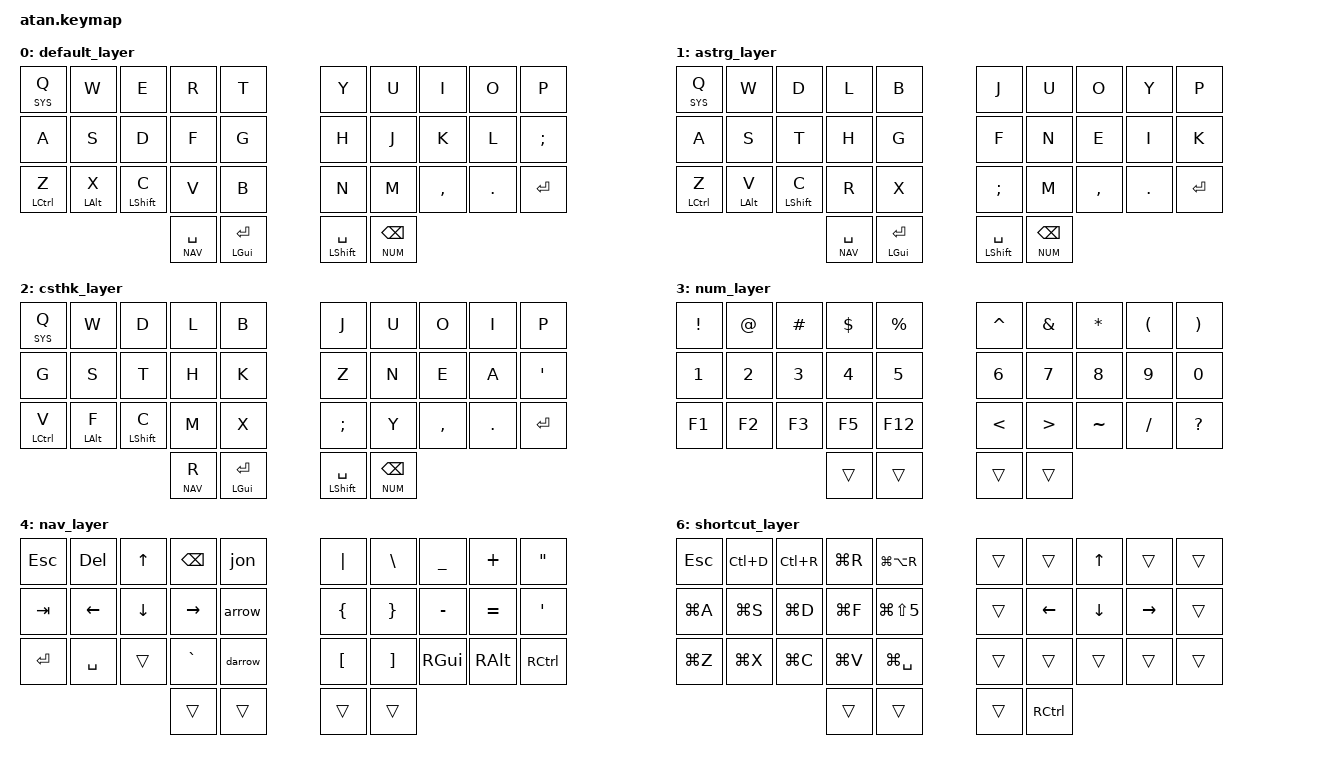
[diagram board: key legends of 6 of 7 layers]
#include <behaviors.dtsi>
#include <dt-bindings/zmk/keys.h>
#include <dt-bindings/zmk/bt.h>

#define QWERT 0
#define ASRT 1
#define CSTH 2
#define NUM 3
#define NAV 4
#define SYS 5
#define SHCT 6


/ {

    behaviors {
        hm: homerow_mods {
            compatible = "zmk,behavior-hold-tap";
            #binding-cells = <2>;
            tapping-term-ms = <150>;
            flavor = "tap-preferred";
            bindings = <&kp>, <&kp>;
        };
    };

    macros {
        jon: jon {
            compatible = "zmk,behavior-macro";
            #binding-cells = <0>;
            bindings
                = <&macro_tap &kp J &kp O &kp N &kp N9 &kp N9 >
                ;
        };
        arrow: arrow {
            compatible = "zmk,behavior-macro";
            #binding-cells = <0>;
            bindings
                = <&macro_tap &kp MINUS &kp GT >
                ;
        };
        darrow: darrow {
            compatible = "zmk,behavior-macro";
            #binding-cells = <0>;
            bindings
                = <&macro_tap &kp EQUAL &kp GT >
                ;
        };
    };

    keymap {
        compatible = "zmk,keymap";


        default_layer {
            bindings = <

                &lt SYS Q   &kp  W    &kp E   &kp  R    &kp T                  &kp  Y    &kp U   &kp I   &kp O &kp  P
                &kp  A     &kp  S    &kp  D    &kp F    &kp G                     &kp H   &kp J    &kp K   &kp  L  &kp SEMI
                &hm LCTRL  Z   &hm LALT X   &hm LSHFT C   &kp V    &kp B             &kp N &kp M  &kp  COMMA   &kp DOT     &kp   RET
                                 &lt NAV SPACE   &hm LGUI    RET          &hm LSHFT SPACE   &lt NUM  BKSP
            >;
        };

        astrg_layer {
            bindings = <

                &lt SYS Q   &kp  W    &kp D   &kp  L    &kp B                  &kp  J    &kp U   &kp O   &kp Y &kp P
                &kp  A     &kp  S    &kp  T    &kp  H  &kp G                     &kp F    &kp N    &kp E   &kp  I   &kp  K
                &hm LCTRL  Z   &hm LALT V   &hm LSHFT C   &kp R   &kp X             &kp SEMI &kp M  &kp  COMMA   &kp DOT     &kp   RET
                                 &lt NAV SPACE   &hm LGUI    RET          &hm LSHFT SPACE   &lt NUM  BKSP
            >;
        };


        csthk_layer {
            bindings = <
                &lt SYS Q   &kp   W    &kp D   &kp  L   &kp  B                &kp  J    &kp U      &kp O  &kp I    &kp  P
                &kp G     &kp  S    &kp  T    &kp   H   &kp  K                      &kp  Z    &kp N  &kp E &kp  A      &kp   SQT
                &hm LCTRL  V   &hm LALT F     &hm LSHFT C &kp M  &kp X           &kp SEMI &kp   Y   &kp  COMMA  &kp DOT     &kp   RET
                                 &lt NAV  R     &hm LGUI    RET          &hm LSHFT SPACE   &lt NUM BKSP
            >;
        };

        num_layer {
            bindings = <
                &kp EXCL   &kp AT   &kp HASH   &kp DOLLAR   &kp PERCENT           &kp CARET   &kp AMPS   &kp STAR   &kp LPAR   &kp RPAR
                &kp N1   &kp N2   &kp N3   &kp N4   &kp N5                          &kp N6   &kp N7  &kp N8   &kp N9   &kp N0
                &kp F1   &kp F2   &kp F3   &kp F5   &kp F12                     &kp LT   &kp GT   &kp TILDE   &kp FSLH   &kp QMARK
                        &trans   &trans                     &trans   &trans
            >;
        };

        nav_layer {
            bindings = <
                &kp ESC   &kp DEL   &kp UP  &kp BSPC    &jon                &kp PIPE    &kp BSLH  &kp UNDER   &kp PLUS   &kp DQT
                &kp TAB   &kp LEFT   &kp DOWN   &kp RIGHT   &arrow           &kp LBRC   &kp RBRC   &kp MINUS   &kp EQUAL    &kp SQT
                &kp RET   &kp SPACE &trans   &kp GRAVE   &darrow       &kp LBKT   &kp RBKT   &kp RGUI   &kp RALT   &kp RCTRL
                        &trans   &trans                     &trans   &trans
            >;
        };

        system_layer {
            bindings = <
                &trans   &bt BT_NXT  &bt BT_PRV  &bt BT_CLR   &trans      &trans   &bt BT_CLR  &bt BT_PRV   &bt BT_NXT  &trans
                 &to 0 &trans   &trans  &trans   &trans               &trans &trans   &trans  &trans   &trans
                 &to 1   &trans  &trans   &trans  &trans              &trans   &trans &trans   &trans  &trans   &trans

                        &trans   &trans                     &trans   &trans
            >;
        };

        shortcut_layer {
            bindings = <

                 &kp ESC    &kp LC(D)   &kp LC(R)   &kp LG(R)   &kp LG(LA(R))                  &trans &trans   &kp UP  &trans   &trans
                &kp LG(A)  &kp LG(S)       &kp LG(D)         &kp LG(F)   &kp LG(LS(N5))        &trans &kp LEFT   &kp DOWN   &kp RIGHT   &trans
                &kp LG(Z) &kp  LG(X)        &kp LG(C)          &kp LG(V)   &kp LG(SPACE)       &trans &trans   &trans  &trans   &trans

                        &trans   &trans                     &trans   &kp RCTRL
            >;
        };

    };
};
